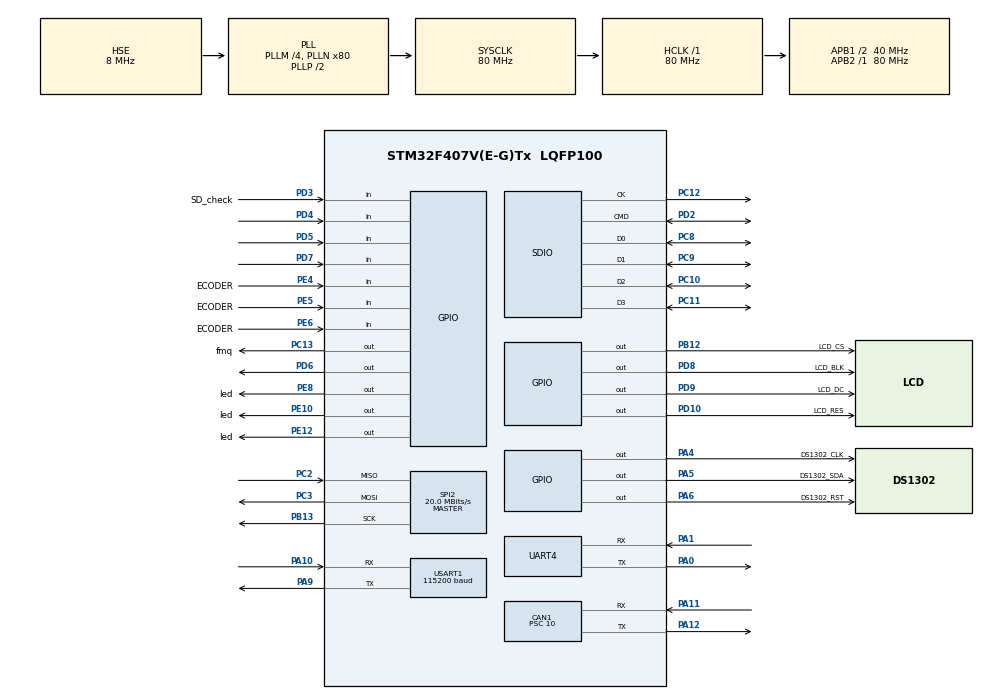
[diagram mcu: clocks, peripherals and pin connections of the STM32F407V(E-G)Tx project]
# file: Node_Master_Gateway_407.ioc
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CAN1.BS1=CAN_BS1_8TQ
CAN1.BS2=CAN_BS2_3TQ
CAN1.CalculateBaudRate=333333
CAN1.CalculateTimeBit=3000
CAN1.CalculateTimeQuantum=250.0
CAN1.Prescaler=10
CAN1.SJW=CAN_SJW_2TQ
Dma.Request0=USART1_RX
Dma.Request1=SPI2_TX
Dma.Request2=SDIO_RX
Dma.Request3=SDIO_TX
Dma.SDIO_RX.2.Direction=DMA_PERIPH_TO_MEMORY
Dma.SDIO_RX.2.FIFOMode=DMA_FIFOMODE_ENABLE
Dma.SDIO_RX.2.FIFOThreshold=DMA_FIFO_THRESHOLD_FULL
Dma.SDIO_RX.2.Instance=DMA2_Stream3
Dma.SDIO_RX.2.MemBurst=DMA_MBURST_INC4
Dma.SDIO_RX.2.MemDataAlignment=DMA_MDATAALIGN_WORD
Dma.SDIO_RX.2.MemInc=DMA_MINC_ENABLE
Dma.SDIO_RX.2.Mode=DMA_PFCTRL
Dma.SDIO_RX.2.PeriphBurst=DMA_PBURST_INC4
Dma.SDIO_RX.2.PeriphDataAlignment=DMA_PDATAALIGN_WORD
Dma.SDIO_RX.2.PeriphInc=DMA_PINC_DISABLE
Dma.SDIO_RX.2.Priority=DMA_PRIORITY_VERY_HIGH
Dma.SDIO_TX.3.Direction=DMA_MEMORY_TO_PERIPH
Dma.SDIO_TX.3.FIFOMode=DMA_FIFOMODE_ENABLE
Dma.SDIO_TX.3.FIFOThreshold=DMA_FIFO_THRESHOLD_FULL
Dma.SDIO_TX.3.Instance=DMA2_Stream6
Dma.SDIO_TX.3.MemBurst=DMA_MBURST_INC4
Dma.SDIO_TX.3.MemDataAlignment=DMA_MDATAALIGN_WORD
Dma.SDIO_TX.3.MemInc=DMA_MINC_ENABLE
Dma.SDIO_TX.3.Mode=DMA_PFCTRL
Dma.SDIO_TX.3.PeriphBurst=DMA_PBURST_INC4
Dma.SDIO_TX.3.PeriphDataAlignment=DMA_PDATAALIGN_WORD
Dma.SDIO_TX.3.PeriphInc=DMA_PINC_DISABLE
Dma.SDIO_TX.3.Priority=DMA_PRIORITY_VERY_HIGH
Dma.SPI2_TX.1.Direction=DMA_MEMORY_TO_PERIPH
Dma.SPI2_TX.1.FIFOMode=DMA_FIFOMODE_DISABLE
Dma.SPI2_TX.1.Instance=DMA1_Stream4
Dma.SPI2_TX.1.MemDataAlignment=DMA_MDATAALIGN_BYTE
Dma.SPI2_TX.1.MemInc=DMA_MINC_ENABLE
Dma.SPI2_TX.1.Mode=DMA_NORMAL
Dma.SPI2_TX.1.PeriphDataAlignment=DMA_PDATAALIGN_BYTE
Dma.SPI2_TX.1.PeriphInc=DMA_PINC_DISABLE
Dma.SPI2_TX.1.Priority=DMA_PRIORITY_LOW
Dma.USART1_RX.0.Direction=DMA_PERIPH_TO_MEMORY
Dma.USART1_RX.0.FIFOMode=DMA_FIFOMODE_ENABLE
Dma.USART1_RX.0.FIFOThreshold=DMA_FIFO_THRESHOLD_FULL
Dma.USART1_RX.0.Instance=DMA2_Stream2
Dma.USART1_RX.0.MemBurst=DMA_MBURST_SINGLE
Dma.USART1_RX.0.MemDataAlignment=DMA_MDATAALIGN_BYTE
Dma.USART1_RX.0.MemInc=DMA_MINC_ENABLE
Dma.USART1_RX.0.Mode=DMA_NORMAL
Dma.USART1_RX.0.PeriphBurst=DMA_PBURST_SINGLE
Dma.USART1_RX.0.PeriphDataAlignment=DMA_PDATAALIGN_BYTE
Dma.USART1_RX.0.PeriphInc=DMA_PINC_DISABLE
Dma.USART1_RX.0.Priority=DMA_PRIORITY_LOW
FATFS.BSP.number=1
FATFS._CODE_PAGE=936
FATFS._FS_LOCK=0
FATFS0.BSP.STBoard=false
FATFS0.BSP.api=Unknown
FATFS0.BSP.instance=PD3
FATFS0.BSP.ip=GPIO
FATFS0.BSP.mode=Input
FATFS0.BSP.name=Detect_SDIO
FATFS0.BSP.solution=PD3
FREERTOS.Queues01=Ec11_Queue,16,uint8_t,0,Dynamic,NULL,NULL
FREERTOS.Tasks01=Cont_Task,24,256,vCont_task,As weak,NULL,Dynamic,NULL,NULL;UI_Task,8,256,vUI_task,As weak,NULL,Dynamic,NULL,NULL;Data_Task,8,256,vData_task,As weak,NULL,Dynamic,NULL,NULL;Process_Task,8,256,vProcess_task,As weak,NULL,Dynamic,NULL,NULL
FREERTOS.configCHECK_FOR_STACK_OVERFLOW=2
FREERTOS.configMINIMAL_STACK_SIZE=128
Mcu.Family=STM32F4
Mcu.Name=STM32F407V(E-G)Tx
Mcu.Package=LQFP100
NVIC.DMA1_Stream4_IRQn=true\:5\:0\:false\:false\:true\:true\:false\:true\:true
NVIC.DMA2_Stream2_IRQn=true\:5\:0\:false\:false\:true\:true\:false\:true\:true
NVIC.DMA2_Stream3_IRQn=true\:5\:0\:false\:false\:true\:true\:false\:true\:true
NVIC.DMA2_Stream6_IRQn=true\:5\:0\:false\:false\:true\:true\:false\:true\:true
NVIC.PriorityGroup=NVIC_PRIORITYGROUP_4
NVIC.SDIO_IRQn=true\:5\:0\:false\:false\:true\:true\:true\:true\:true
NVIC.SPI2_IRQn=true\:5\:0\:false\:false\:true\:true\:true\:true\:true
NVIC.TIM6_DAC_IRQn=true\:5\:0\:true\:false\:true\:true\:true\:true\:true
NVIC.TIM7_IRQn=true\:0\:0\:true\:false\:true\:false\:false\:true\:true
NVIC.TimeBase=TIM7_IRQn
NVIC.TimeBaseIP=TIM7
NVIC.USART1_IRQn=true\:5\:0\:false\:false\:false\:true\:true\:true\:true
PA0-WKUP.Mode=Asynchronous
PA0-WKUP.Signal=UART4_TX
PA1.Mode=Asynchronous
PA1.Signal=UART4_RX
PA10.Mode=Asynchronous
PA10.Signal=USART1_RX
PA11.Mode=CAN_Activate
PA11.Signal=CAN1_RX
PA12.Mode=CAN_Activate
PA12.Signal=CAN1_TX
PA13.Mode=Serial_Wire
PA13.Signal=SYS_JTMS-SWDIO
PA14.Mode=Serial_Wire
PA14.Signal=SYS_JTCK-SWCLK
PA4.GPIO_Label=DS1302_CLK
PA4.GPIO_Speed=GPIO_SPEED_FREQ_HIGH
PA4.PinState=GPIO_PIN_RESET
PA4.Signal=GPIO_Output
PA5.GPIO_Label=DS1302_SDA
PA5.GPIO_ModeDefaultOutputPP=GPIO_MODE_OUTPUT_OD
PA5.GPIO_PuPd=GPIO_PULLUP
PA5.GPIO_Speed=GPIO_SPEED_FREQ_HIGH
PA5.PinState=GPIO_PIN_RESET
PA5.Signal=GPIO_Output
PA6.GPIO_Label=DS1302_RST
PA6.GPIO_PuPd=GPIO_NOPULL
PA6.GPIO_Speed=GPIO_SPEED_FREQ_HIGH
PA6.PinState=GPIO_PIN_RESET
PA6.Signal=GPIO_Output
PA9.Mode=Asynchronous
PA9.Signal=USART1_TX
PB12.GPIO_Label=LCD_CS
PB12.GPIO_Speed=GPIO_SPEED_FREQ_VERY_HIGH
PB12.PinState=GPIO_PIN_RESET
PB12.Signal=GPIO_Output
PB13.Mode=Full_Duplex_Master
PB13.Signal=SPI2_SCK
PC10.Mode=SD_4_bits_Wide_bus
PC10.Signal=SDIO_D2
PC11.Mode=SD_4_bits_Wide_bus
PC11.Signal=SDIO_D3
PC12.Mode=SD_4_bits_Wide_bus
PC12.Signal=SDIO_CK
PC13-ANTI_TAMP.GPIO_Label=fmq
PC13-ANTI_TAMP.Signal=GPIO_Output
PC2.Mode=Full_Duplex_Master
PC2.Signal=SPI2_MISO
PC3.Mode=Full_Duplex_Master
PC3.Signal=SPI2_MOSI
PC8.Mode=SD_4_bits_Wide_bus
PC8.Signal=SDIO_D0
PC9.Mode=SD_4_bits_Wide_bus
PC9.Signal=SDIO_D1
PD10.GPIO_Label=LCD_RES
PD10.GPIO_ModeDefaultOutputPP=GPIO_MODE_OUTPUT_PP
PD10.GPIO_PuPd=GPIO_NOPULL
PD10.GPIO_Speed=GPIO_SPEED_FREQ_VERY_HIGH
PD10.PinState=GPIO_PIN_RESET
PD10.Signal=GPIO_Output
PD2.Mode=SD_4_bits_Wide_bus
PD2.Signal=SDIO_CMD
PD3.GPIO_Label=SD_check
PD3.GPIO_PuPd=GPIO_PULLUP
PD3.Signal=GPIO_Input
PD4.GPIO_PuPd=GPIO_PULLUP
PD4.Signal=GPIO_Input
PD5.GPIO_PuPd=GPIO_PULLUP
PD5.Signal=GPIO_Input
PD6.GPIO_PuPd=GPIO_PULLUP
PD6.Signal=GPIO_Output
PD7.GPIO_PuPd=GPIO_PULLUP
PD7.Signal=GPIO_Input
PD8.GPIO_Label=LCD_BLK
PD8.GPIO_ModeDefaultOutputPP=GPIO_MODE_OUTPUT_PP
PD8.GPIO_PuPd=GPIO_NOPULL
PD8.GPIO_Speed=GPIO_SPEED_FREQ_VERY_HIGH
PD8.PinState=GPIO_PIN_RESET
PD8.Signal=GPIO_Output
PD9.GPIO_Label=LCD_DC
PD9.GPIO_ModeDefaultOutputPP=GPIO_MODE_OUTPUT_PP
PD9.GPIO_PuPd=GPIO_NOPULL
PD9.GPIO_Speed=GPIO_SPEED_FREQ_VERY_HIGH
PD9.PinState=GPIO_PIN_RESET
PD9.Signal=GPIO_Output
PE10.GPIO_Label=led
PE10.GPIO_ModeDefaultOutputPP=GPIO_MODE_OUTPUT_PP
PE10.GPIO_PuPd=GPIO_NOPULL
PE10.GPIO_Speed=GPIO_SPEED_FREQ_LOW
PE10.PinState=GPIO_PIN_RESET
PE10.Signal=GPIO_Output
PE12.GPIO_Label=led
PE12.GPIO_ModeDefaultOutputPP=GPIO_MODE_OUTPUT_PP
PE12.GPIO_PuPd=GPIO_NOPULL
PE12.GPIO_Speed=GPIO_SPEED_FREQ_LOW
PE12.PinState=GPIO_PIN_RESET
PE12.Signal=GPIO_Output
PE4.GPIO_Label=ECODER
PE4.GPIO_PuPd=GPIO_PULLUP
PE4.Signal=GPIO_Input
PE5.GPIO_Label=ECODER
PE5.GPIO_PuPd=GPIO_PULLUP
PE5.Signal=GPIO_Input
PE6.GPIO_Label=ECODER
PE6.GPIO_PuPd=GPIO_PULLUP
PE6.Signal=GPIO_Input
PE8.GPIO_Label=led
PE8.GPIO_ModeDefaultOutputPP=GPIO_MODE_OUTPUT_PP
PE8.GPIO_PuPd=GPIO_NOPULL
PE8.GPIO_Speed=GPIO_SPEED_FREQ_LOW
PE8.PinState=GPIO_PIN_RESET
PE8.Signal=GPIO_Output
PH0-OSC_IN.Mode=HSE-External-Oscillator
PH0-OSC_IN.Signal=RCC_OSC_IN
PH1-OSC_OUT.Mode=HSE-External-Oscillator
PH1-OSC_OUT.Signal=RCC_OSC_OUT
ProjectManager.HeapSize=0x200
ProjectManager.StackSize=0x400
ProjectManager.TargetToolchain=CMake
RCC.48MHZClocksFreq_Value=40000000
RCC.AHBFreq_Value=80000000
RCC.APB1CLKDivider=RCC_HCLK_DIV2
RCC.APB1Freq_Value=40000000
RCC.APB1TimFreq_Value=80000000
RCC.APB2Freq_Value=80000000
RCC.APB2TimFreq_Value=80000000
RCC.CortexFreq_Value=80000000
RCC.HCLKFreq_Value=80000000
RCC.HSE_VALUE=8000000
RCC.HSI_VALUE=16000000
RCC.LSE_VALUE=32768
RCC.PLLM=4
RCC.PLLN=80
RCC.PLLSourceVirtual=RCC_PLLSOURCE_HSE
RCC.SYSCLKFreq_VALUE=80000000
RCC.SYSCLKSource=RCC_SYSCLKSOURCE_PLLCLK
RCC.VCOOutputFreq_Value=160000000
SDIO.ClockDiv=0
SPI2.BaudRatePrescaler=SPI_BAUDRATEPRESCALER_2
SPI2.CalculateBaudRate=20.0 MBits/s
SPI2.Direction=SPI_DIRECTION_2LINES
SPI2.Mode=SPI_MODE_MASTER
SPI2.VirtualType=VM_MASTER
TIM6.Period=200-1
TIM6.Prescaler=800-1
UART4.VirtualMode=Asynchronous
USART1.BaudRate=115200
USART1.VirtualMode=VM_ASYNC
VP_FATFS_VS_SDIO.Mode=SDIO
VP_FREERTOS_VS_CMSIS_V2.Mode=CMSIS_V2
VP_SYS_VS_tim7.Mode=TIM7
VP_TIM6_VS_ClockSourceINT.Mode=Enable_Timer
board=custom

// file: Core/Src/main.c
/* USER CODE BEGIN Header */
/**
  ******************************************************************************
  * @file           : main.c
  * @brief          : Main program body
  ******************************************************************************
  * @attention
  *
  * Copyright (c) 2026 STMicroelectronics.
  * All rights reserved.
  *
  * This software is licensed under terms that can be found in the LICENSE file
  * in the root directory of this software component.
  * If no LICENSE file comes with this software, it is provided AS-IS.
  *
  ******************************************************************************
  */
/* USER CODE END Header */
#include "main.h"
#include "cmsis_os.h"
#include "can.h"
#include "dma.h"
#include "fatfs.h"
#include "sdio.h"
#include "spi.h"
#include "tim.h"
#include "usart.h"
#include "gpio.h"

/* USER CODE BEGIN Includes */
#include "app_display.h"
#include "ecode.h"
#include <stdint.h>
/* USER CODE END Includes */

void SystemClock_Config(void);
void MX_FREERTOS_Init(void);

int main(void)
{

  /* MCU Configuration--------------------------------------------------------*/

  /* Reset of all peripherals, Initializes the Flash interface and the Systick. */
  HAL_Init();

  /* Configure the system clock */
  SystemClock_Config();

  /* Initialize all configured peripherals */
  MX_GPIO_Init();
  MX_DMA_Init();
  MX_CAN1_Init();
  MX_SPI2_Init();
  MX_USART1_UART_Init();
  MX_UART4_Init();
  MX_SDIO_SD_Init();
  MX_FATFS_Init();
  MX_TIM6_Init();

  /* Init scheduler */
  osKernelInitialize();  /* Call init function for freertos objects (in cmsis_os2.c) */
  MX_FREERTOS_Init();

  /* Start scheduler */
  osKernelStart();

  /* We should never get here as control is now taken by the scheduler */

  /* Infinite loop */
  while (1)
  {

  }
}

void SystemClock_Config(void)
{
  RCC_OscInitTypeDef RCC_OscInitStruct = {0};
  RCC_ClkInitTypeDef RCC_ClkInitStruct = {0};

  /** Configure the main internal regulator output voltage
  */
  __HAL_RCC_PWR_CLK_ENABLE();
  __HAL_PWR_VOLTAGESCALING_CONFIG(PWR_REGULATOR_VOLTAGE_SCALE1);

  /** Initializes the RCC Oscillators according to the specified parameters
  * in the RCC_OscInitTypeDef structure.
  */
  RCC_OscInitStruct.OscillatorType = RCC_OSCILLATORTYPE_HSE;
  RCC_OscInitStruct.HSEState = RCC_HSE_ON;
  RCC_OscInitStruct.PLL.PLLState = RCC_PLL_ON;
  RCC_OscInitStruct.PLL.PLLSource = RCC_PLLSOURCE_HSE;
  RCC_OscInitStruct.PLL.PLLM = 4;
  RCC_OscInitStruct.PLL.PLLN = 80;
  RCC_OscInitStruct.PLL.PLLP = RCC_PLLP_DIV2;
  RCC_OscInitStruct.PLL.PLLQ = 4;
  if (HAL_RCC_OscConfig(&RCC_OscInitStruct) != HAL_OK)
  {
    Error_Handler();
  }

  /** Initializes the CPU, AHB and APB buses clocks
  */
  RCC_ClkInitStruct.ClockType = RCC_CLOCKTYPE_HCLK|RCC_CLOCKTYPE_SYSCLK
                              |RCC_CLOCKTYPE_PCLK1|RCC_CLOCKTYPE_PCLK2;
  RCC_ClkInitStruct.SYSCLKSource = RCC_SYSCLKSOURCE_PLLCLK;
  RCC_ClkInitStruct.AHBCLKDivider = RCC_SYSCLK_DIV1;
  RCC_ClkInitStruct.APB1CLKDivider = RCC_HCLK_DIV2;
  RCC_ClkInitStruct.APB2CLKDivider = RCC_HCLK_DIV1;

  if (HAL_RCC_ClockConfig(&RCC_ClkInitStruct, FLASH_LATENCY_2) != HAL_OK)
  {
    Error_Handler();
  }
}

void HAL_TIM_PeriodElapsedCallback(TIM_HandleTypeDef *htim)
{
  if (htim->Instance == TIM7)
  {
    HAL_IncTick();
  }
  if (htim->Instance == TIM6) {
       extern ecode_dev ecode_one;
    ecode_getstate(&ecode_one);
  }
}

void Error_Handler(void)
{
  __disable_irq();
  while (1)
  {
  }
}

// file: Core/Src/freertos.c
/* USER CODE BEGIN Header */
/**
  ******************************************************************************
  * File Name          : freertos.c
  * Description        : Code for freertos applications
  ******************************************************************************
  * @attention
  *
  * Copyright (c) 2026 STMicroelectronics.
  * All rights reserved.
  *
  * This software is licensed under terms that can be found in the LICENSE file
  * in the root directory of this software component.
  * If no LICENSE file comes with this software, it is provided AS-IS.
  *
  ******************************************************************************
  */
/* USER CODE END Header */

#include "FreeRTOS.h"
#include "task.h"
#include "main.h"
#include "cmsis_os.h"

/* USER CODE BEGIN Includes */
#include <stdio.h>
/* USER CODE END Includes */

/* Definitions for Cont_Task */
osThreadId_t Cont_TaskHandle;
const osThreadAttr_t Cont_Task_attributes = {
  .name = "Cont_Task",
  .stack_size = 256 * 4,
  .priority = (osPriority_t) osPriorityNormal,
};
/* Definitions for UI_Task */
osThreadId_t UI_TaskHandle;
const osThreadAttr_t UI_Task_attributes = {
  .name = "UI_Task",
  .stack_size = 256 * 4,
  .priority = (osPriority_t) osPriorityLow,
};
/* Definitions for Data_Task */
osThreadId_t Data_TaskHandle;
const osThreadAttr_t Data_Task_attributes = {
  .name = "Data_Task",
  .stack_size = 256 * 4,
  .priority = (osPriority_t) osPriorityLow,
};
/* Definitions for Process_Task */
osThreadId_t Process_TaskHandle;
const osThreadAttr_t Process_Task_attributes = {
  .name = "Process_Task",
  .stack_size = 256 * 4,
  .priority = (osPriority_t) osPriorityLow,
};
/* Definitions for Ec11_Queue */
osMessageQueueId_t Ec11_QueueHandle;
const osMessageQueueAttr_t Ec11_Queue_attributes = {
  .name = "Ec11_Queue"
};

void vCont_task(void *argument);
void vUI_task(void *argument);
void vData_task(void *argument);
void vProcess_task(void *argument);

void MX_FREERTOS_Init(void); /* (MISRA C 2004 rule 8.1) */

/* Hook prototypes */
void vApplicationStackOverflowHook(xTaskHandle xTask, signed char *pcTaskName);

/* USER CODE BEGIN 4 */
void vApplicationStackOverflowHook(xTaskHandle xTask, signed char *pcTaskName)
{
   /* Run time stack overflow checking is performed if
   configCHECK_FOR_STACK_OVERFLOW is defined to 1 or 2. This hook function is
   called if a stack overflow is detected. */
   /* 一旦任务切换检测到栈溢出，内核会主动跳进这里 */
   /* 1. 先用 volatile 变量存下名字，方便仿真器直观查看 */
    volatile signed char *overflow_task = pcTaskName;
    (void)overflow_task;
    (void)xTask;          //这样是为了方便溢出串口无法工作 通过断点查看
    printf("发生栈溢出！任务名: %s\r\n", pcTaskName);
    __disable_irq(); // 关全局中断，冻结案发现场
    while(1);        // 在这里打断点
}
/* USER CODE END 4 */

void MX_FREERTOS_Init(void) {

  /* Create the queue(s) */
  /* creation of Ec11_Queue */
  Ec11_QueueHandle = osMessageQueueNew (16, sizeof(uint8_t), &Ec11_Queue_attributes);

  /* Create the thread(s) */
  /* creation of Cont_Task */
  Cont_TaskHandle = osThreadNew(vCont_task, NULL, &Cont_Task_attributes);

  /* creation of UI_Task */
  UI_TaskHandle = osThreadNew(vUI_task, NULL, &UI_Task_attributes);

  /* creation of Data_Task */
  Data_TaskHandle = osThreadNew(vData_task, NULL, &Data_Task_attributes);

  /* creation of Process_Task */
  Process_TaskHandle = osThreadNew(vProcess_task, NULL, &Process_Task_attributes);

}

__weak void vCont_task(void *argument)
{
  for(;;)
  {
    osDelay(1);
  }
}

__weak void vUI_task(void *argument)
{
  for(;;)
  {
    osDelay(1);
  }
}

__weak void vData_task(void *argument)
{
  for(;;)
  {
    osDelay(1);
  }
}

__weak void vProcess_task(void *argument)
{
  for(;;)
  {
    osDelay(1);
  }
}
